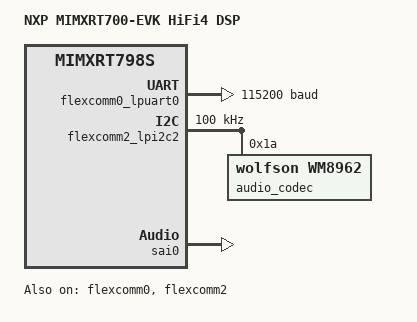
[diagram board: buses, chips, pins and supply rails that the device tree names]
/*
 * Copyright 2024, 2025 NXP
 *
 * SPDX-License-Identifier: Apache-2.0
 */

/dts-v1/;

#include <zephyr/dt-bindings/i2c/i2c.h>
#include <zephyr/dt-bindings/gpio/gpio.h>
#include <zephyr/dt-bindings/input/input-event-codes.h>

#include <nxp/nxp_imxrt700_hifi4.dtsi>

#include "mimxrt700_evk-pinctrl.dtsi"

/ {
	model = "NXP MIMXRT700-EVK HiFi4 DSP";
	compatible = "nxp,mimxrt798s";

	aliases {
		i2s-codec-tx = &sai0;
		i2s-tx = &sai0;
	};

	chosen {
		zephyr,sram = &adsp_data;
		zephyr,console = &flexcomm0_lpuart0;
		zephyr,shell-uart = &flexcomm0_lpuart0;
	};
};

&flexcomm0 {
	status = "okay";
};

&flexcomm0_lpuart0 {
	status = "okay";
	current-speed = <115200>;
	pinctrl-0 = <&pinmux_flexcomm0_lpuart>;
	pinctrl-names = "default";
};

&flexcomm2 {
	status = "okay";
};

&flexcomm2_lpi2c2 {
	status = "okay";
	pinctrl-0 = <&pinmux_flexcomm2_i2c>;
	pinctrl-names = "default";
	clock-frequency = <I2C_BITRATE_STANDARD>;
	#address-cells = <1>;
	#size-cells = <0>;

	audio_codec: wm8962@1a {
		compatible = "wolfson,wm8962";
		reg = <0x1a>;
		clock-source = "MCLK";
		clocks = <&clkctl0 MCUX_SAI0_CLK>;
		clock-names = "mclk";
	};
};

&edma1 {
	status = "okay";
};

&sai0 {
	status = "okay";
	pinctrl-0 = <&pinmux_sai0>;
	pinctrl-names = "default";
	mclk-output;
};

&mbox4 {
	status = "okay";
};
